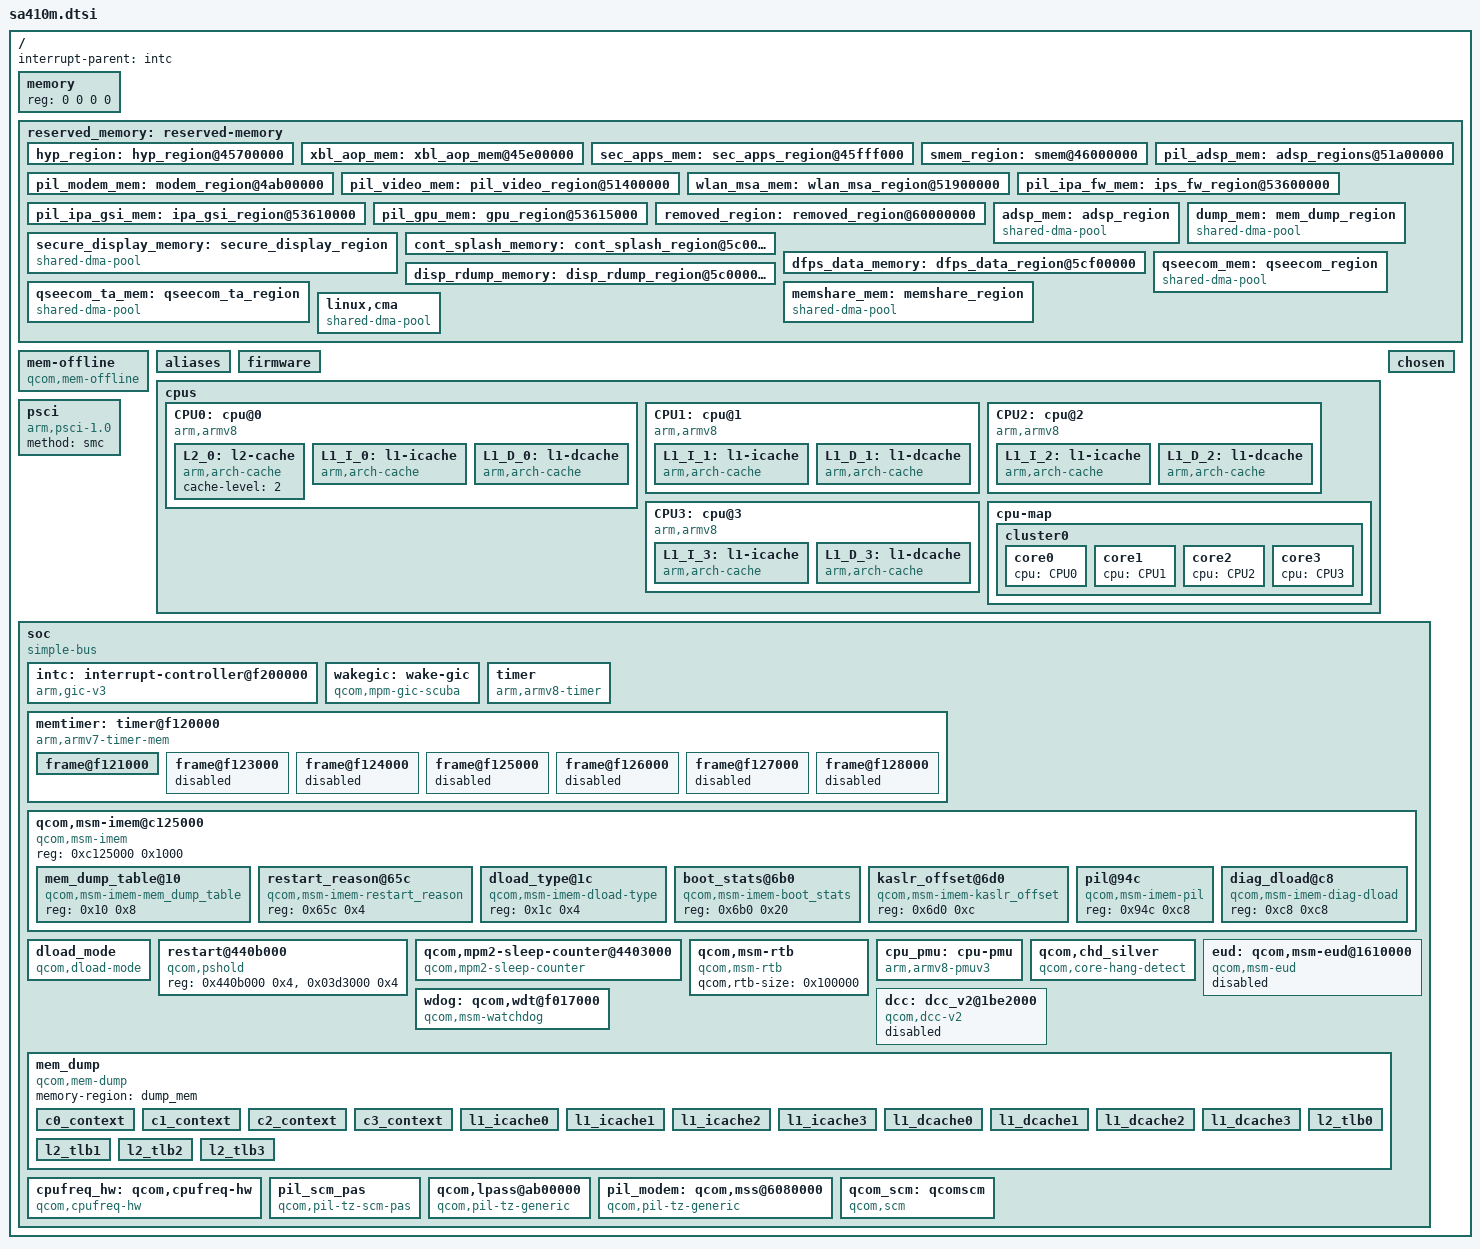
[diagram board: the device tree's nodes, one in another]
#include <dt-bindings/interrupt-controller/arm-gic.h>
#include <dt-bindings/gpio/gpio.h>

/ {
	#address-cells = <2>;
	#size-cells = <2>;
	interrupt-parent = <&intc>;

	memory { device_type = "memory"; reg = <0 0 0 0>; };

	reserved_memory: reserved-memory { };

	mem-offline {
		compatible = "qcom,mem-offline";
		offline-sizes = <0x1 0x40000000 0x0 0x40000000>,
				<0x1 0xc0000000 0x0 0x80000000>,
				<0x2 0xc0000000 0x1 0x40000000>;
		granule = <512>;
	};

	aliases {};

	firmware: firmware {};

	cpus {
		#address-cells = <2>;
		#size-cells = <0>;

		CPU0: cpu@0 {
			device_type = "cpu";
			compatible = "arm,armv8";
			reg = <0x0 0x0>;
			enable-method = "psci";
			capacity-dmips-mhz = <1024>;
			dynamic-power-coefficient = <100>;
			next-level-cache = <&L2_0>;
			qcom,freq-domain = <&cpufreq_hw 0 4>;
			L2_0: l2-cache {
				compatible = "arm,arch-cache";
				cache-level = <2>;
			};

			L1_I_0: l1-icache {
				compatible = "arm,arch-cache";
			};

			L1_D_0: l1-dcache {
				compatible = "arm,arch-cache";
			};
		};

		CPU1: cpu@1 {
			device_type = "cpu";
			compatible = "arm,armv8";
			reg = <0x0 0x1>;
			enable-method = "psci";
			capacity-dmips-mhz = <1024>;
			dynamic-power-coefficient = <100>;
			next-level-cache = <&L2_0>;
			qcom,freq-domain = <&cpufreq_hw 0 4>;

			L1_I_1: l1-icache {
				compatible = "arm,arch-cache";
			};

			L1_D_1: l1-dcache {
				compatible = "arm,arch-cache";
			};
		};

		CPU2: cpu@2 {
			device_type = "cpu";
			compatible = "arm,armv8";
			reg = <0x0 0x2>;
			enable-method = "psci";
			capacity-dmips-mhz = <1024>;
			dynamic-power-coefficient = <100>;
			next-level-cache = <&L2_0>;
			qcom,freq-domain = <&cpufreq_hw 0 4>;

			L1_I_2: l1-icache {
				compatible = "arm,arch-cache";
			};

			L1_D_2: l1-dcache {
				compatible = "arm,arch-cache";
			};
		};

		CPU3: cpu@3 {
			device_type = "cpu";
			compatible = "arm,armv8";
			reg = <0x0 0x3>;
			enable-method = "psci";
			capacity-dmips-mhz = <1024>;
			dynamic-power-coefficient = <100>;
			next-level-cache = <&L2_0>;
			qcom,freq-domain = <&cpufreq_hw 0 4>;

			L1_I_3: l1-icache {
				compatible = "arm,arch-cache";
			};

			L1_D_3: l1-dcache {
				compatible = "arm,arch-cache";
			};
		};

		cpu-map {
			cluster0 {
				core0 {
					cpu = <&CPU0>;
				};

				core1 {
					cpu = <&CPU1>;
				};

				core2 {
					cpu = <&CPU2>;
				};

				core3 {
					cpu = <&CPU3>;
				};
			};
		};
	};

	psci {
		compatible = "arm,psci-1.0";
		method = "smc";
	};

	chosen {
		bootargs = "rcupdate.rcu_expedited=1 rcu_nocbs=0-7";
	};

	soc: soc { };
};

&reserved_memory {
	#address-cells = <2>;
	#size-cells = <2>;
	ranges;

	hyp_region: hyp_region@45700000 {
		no-map;
		reg = <0x0 0x45700000 0x0 0x600000>;
	};

	xbl_aop_mem: xbl_aop_mem@45e00000 {
		no-map;
		reg = <0x0 0x45e00000 0x0 0x100000>;
	};

	sec_apps_mem: sec_apps_region@45fff000 {
		no-map;
		reg = <0x0 0x45fff000 0x0 0x1000>;
	};

	smem_region: smem@46000000 {
		no-map;
		reg = <0x0 0x46000000 0x0 0x200000>;
	};

	pil_modem_mem: modem_region@4ab00000 {
		no-map;
		reg = <0x0 0x4ab00000 0x0 0x6900000>;
	};

	pil_video_mem: pil_video_region@51400000 {
		no-map;
		reg = <0x0 0x51400000 0x0 0x500000>;
	};

	wlan_msa_mem: wlan_msa_region@51900000 {
		no-map;
		reg = <0x0 0x51900000 0x0 0x100000>;
	};

	pil_adsp_mem: adsp_regions@51a00000 {
		no-map;
		reg = <0x0 0x51a00000 0x0 0x1c00000>;
	};

	pil_ipa_fw_mem: ips_fw_region@53600000 {
		no-map;
		reg = <0x0 0x53600000 0x0 0x10000>;
	};

	pil_ipa_gsi_mem: ipa_gsi_region@53610000 {
		no-map;
		reg = <0x0 0x53610000 0x0 0x5000>;
	};

	pil_gpu_mem: gpu_region@53615000 {
		no-map;
		reg = <0x0 0x53615000 0x0 0x2000>;
	};

	removed_region: removed_region@60000000 {
		no-map;
		reg = <0x0 0x60000000 0x0 0x3900000>;
	};

	adsp_mem: adsp_region {
		compatible = "shared-dma-pool";
		alloc-ranges = <0 0x00000000 0 0xffffffff>;
		reusable;
		alignment = <0 0x400000>;
		size = <0 0x800000>;
	};

	dump_mem: mem_dump_region {
		compatible = "shared-dma-pool";
		alloc-ranges = <0x0 0x00000000 0x0 0xffffffff>;
		reusable;
		size = <0 0x800000>;
	};

	secure_display_memory: secure_display_region {
		compatible = "shared-dma-pool";
		alloc-ranges = <0 0x00000000 0 0xffffffff>;
		reusable;
		alignment = <0 0x400000>;
		size = <0 0x5c00000>;
	};

	cont_splash_memory: cont_splash_region@5c000000 {
		reg = <0x0 0x5c000000 0x0 0x00f00000>;
		label = "cont_splash_region";
	};

	dfps_data_memory: dfps_data_region@5cf00000 {
		reg = <0x0 0x5cf00000 0x0 0x0100000>;
		label = "dfps_data_region";
	};

	disp_rdump_memory: disp_rdump_region@5c000000 {
		reg = <0x0 0x5c000000 0x0 0x00f00000>;
		label = "disp_rdump_region";
	};

	qseecom_mem: qseecom_region {
		compatible = "shared-dma-pool";
		alloc-ranges = <0x0 0x00000000 0x0 0xffffffff>;
		reusable;
		alignment = <0x0 0x400000>;
		size = <0x0 0x1400000>;
	};

	qseecom_ta_mem: qseecom_ta_region {
		compatible = "shared-dma-pool";
		alloc-ranges = <0x0 0x00000000 0x0 0xffffffff>;
		reusable;
		alignment = <0x0 0x400000>;
		size = <0x0 0x1000000>;
	};

	memshare_mem: memshare_region {
		compatible = "shared-dma-pool";
		no-map;
		alloc-ranges = <0x0 0x00000000 0x0 0xffffffff>;
		alignment = <0x0 0x100000>;
		size = <0x0 0x800000>;
	};

	/* global autoconfigured region for contiguous allocations */
	linux,cma {
		compatible = "shared-dma-pool";
		alloc-ranges = <0x0 0x00000000 0x0 0xffffffff>;
		reusable;
		alignment = <0x0 0x400000>;
		size = <0x0 0x2000000>;
		linux,cma-default;
	};
};

&soc {
	#address-cells = <1>;
	#size-cells = <1>;
	ranges = <0 0 0 0xffffffff>;
	compatible = "simple-bus";

	intc: interrupt-controller@f200000 {
		compatible = "arm,gic-v3";
		#interrupt-cells = <3>;
		interrupt-controller;
		interrupt-parent = <&intc>;
		#redistributor-regions = <1>;
		redistributor-stride = <0x0 0x20000>;
		reg = <0xf200000 0x10000>,     /* GICD */
		      <0xf300000 0x100000>;    /* GICR * 8 */
		interrupts = <GIC_PPI 9 IRQ_TYPE_LEVEL_HIGH>;
		#gpio-cells = <0>;
	};

	wakegic: wake-gic {
		compatible = "qcom,mpm-gic-scuba", "qcom,mpm";
		interrupts = <GIC_SPI 197 IRQ_TYPE_EDGE_RISING>;
		reg = <0x45f01b8 0x1000>,
			<0x0f40000c 0x4>;  /* MSM_APCS_GCC_BASE 4K */
		reg-names = "vmpm", "ipc";
		qcom,num-mpm-irqs = <96>;
		interrupt-controller;
		interrupt-parent = <&intc>;
		#interrupt-cells = <2>;
	};

	timer {
		compatible = "arm,armv8-timer";
		interrupts = <GIC_PPI 1 (GIC_CPU_MASK_SIMPLE(8) | IRQ_TYPE_LEVEL_LOW)>,
			     <GIC_PPI 2 (GIC_CPU_MASK_SIMPLE(8) | IRQ_TYPE_LEVEL_LOW)>,
			     <GIC_PPI 3 (GIC_CPU_MASK_SIMPLE(8) | IRQ_TYPE_LEVEL_LOW)>,
			     <GIC_PPI 0 (GIC_CPU_MASK_SIMPLE(8) | IRQ_TYPE_LEVEL_LOW)>;
		clock-frequency = <19200000>;
	};

	memtimer: timer@f120000 {
		#address-cells = <1>;
		#size-cells = <1>;
		ranges;
		compatible = "arm,armv7-timer-mem";
		reg = <0xf120000 0x1000>;
		clock-frequency = <19200000>;

		frame@f121000 {
			frame-number = <0>;
			interrupts = <GIC_SPI 8 IRQ_TYPE_LEVEL_HIGH>,
				     <GIC_SPI 7 IRQ_TYPE_LEVEL_HIGH>;
			reg = <0xf121000 0x1000>,
			      <0xf122000 0x1000>;
		};

		frame@f123000 {
			frame-number = <1>;
			interrupts = <GIC_SPI 9 IRQ_TYPE_LEVEL_HIGH>;
			reg = <0xf123000 0x1000>;
			status = "disabled";
		};

		frame@f124000 {
			frame-number = <2>;
			interrupts = <GIC_SPI 10 IRQ_TYPE_LEVEL_HIGH>;
			reg = <0xf124000 0x1000>;
			status = "disabled";
		};

		frame@f125000 {
			frame-number = <3>;
			interrupts = <GIC_SPI 11 IRQ_TYPE_LEVEL_HIGH>;
			reg = <0xf125000 0x1000>;
			status = "disabled";
		};

		frame@f126000 {
			frame-number = <4>;
			interrupts = <GIC_SPI 12 IRQ_TYPE_LEVEL_HIGH>;
			reg = <0xf126000 0x1000>;
			status = "disabled";
		};

		frame@f127000 {
			frame-number = <5>;
			interrupts = <GIC_SPI 13 IRQ_TYPE_LEVEL_HIGH>;
			reg = <0xf127000 0x1000>;
			status = "disabled";
		};

		frame@f128000 {
			frame-number = <6>;
			interrupts = <GIC_SPI 14 IRQ_TYPE_LEVEL_HIGH>;
			reg = <0xf128000 0x1000>;
			status = "disabled";
		};
	};

	qcom,msm-imem@c125000 {
		compatible = "qcom,msm-imem";
		reg = <0xc125000 0x1000>;
		ranges = <0x0 0xc125000 0x1000>;
		#address-cells = <1>;
		#size-cells = <1>;

		mem_dump_table@10 {
			compatible = "qcom,msm-imem-mem_dump_table";
			reg = <0x10 0x8>;
		};

		restart_reason@65c {
			compatible = "qcom,msm-imem-restart_reason";
			reg = <0x65c 0x4>;
		};

		dload_type@1c {
			compatible = "qcom,msm-imem-dload-type";
			reg = <0x1c 0x4>;
		};

		boot_stats@6b0 {
			compatible = "qcom,msm-imem-boot_stats";
			reg = <0x6b0 0x20>;
		};

		kaslr_offset@6d0 {
			compatible = "qcom,msm-imem-kaslr_offset";
			reg = <0x6d0 0xc>;
		};

		pil@94c {
			compatible = "qcom,msm-imem-pil";
			reg = <0x94c 0xc8>;
		};

		diag_dload@c8 {
			compatible = "qcom,msm-imem-diag-dload";
			reg = <0xc8 0xc8>;
		};
	};

	dload_mode {
		compatible = "qcom,dload-mode";
	};

	restart@440b000 {
		compatible = "qcom,pshold";
		reg = <0x440b000 0x4>,
		      <0x03d3000 0x4>;
		reg-names = "pshold-base", "tcsr-boot-misc-detect";
		status="ok";
	};

	qcom,mpm2-sleep-counter@4403000 {
		compatible = "qcom,mpm2-sleep-counter";
		reg = <0x4403000 0x1000>;
		clock-frequency = <32768>;
	};

	qcom,msm-rtb {
		compatible = "qcom,msm-rtb";
		qcom,rtb-size = <0x100000>;
	};

	cpu_pmu: cpu-pmu {
		compatible = "arm,armv8-pmuv3";
		qcom,irq-is-percpu;
		interrupts = <GIC_PPI 6 IRQ_TYPE_LEVEL_HIGH>;
	};

	qcom,chd_silver {
		compatible = "qcom,core-hang-detect";
		label = "silver";
		qcom,threshold-arr = <0x0f1880b0 0x0f1980b0
				      0x0f1a80b0 0x0f1b80b0>;
		qcom,config-arr = <0x0f1880b8 0x0f1980b8
				   0x0f1a80b8 0x0f1b80b8>;
	};

	eud: qcom,msm-eud@1610000 {
		compatible = "qcom,msm-eud";
		interrupt-names = "eud_irq";
		interrupts = <GIC_SPI 189 IRQ_TYPE_LEVEL_HIGH>;
		reg = <0x1610000 0x2000>,
		      <0x1612000 0x1000>,
		      <0x3E5018 0x4>;
		reg-names = "eud_base", "eud_mode_mgr2",
				"eud_tcsr_check_reg";
		qcom,secure-eud-en;
		qcom,eud-tcsr-check-enable;
		qcom,eud-clock-vote-req;
		//clocks = <&gcc GCC_AHB2PHY_USB_CLK>;
		//clock-names = "eud_ahb2phy_clk";
		status = "disabled";
	};

	wdog: qcom,wdt@f017000 {
		compatible = "qcom,msm-watchdog";
		reg = <0xf017000 0x1000>;
		reg-names = "wdt-base";
		interrupts = <GIC_SPI 3 IRQ_TYPE_EDGE_RISING>,
				<GIC_SPI 4 IRQ_TYPE_LEVEL_HIGH>;
		qcom,bark-time = <11000>;
		qcom,pet-time = <9360>;
		qcom,ipi-ping;
		qcom,wakeup-enable;
		status = "ok";
	};

	dcc: dcc_v2@1be2000 {
		compatible = "qcom,dcc-v2";
		reg = <0x1be2000 0x1000>,
			<0x1bee000 0x2000>;
		reg-names = "dcc-base", "dcc-ram-base";
		dcc-ram-offset = <0x2000>;
		status = "disabled";
	};

	mem_dump {
		compatible = "qcom,mem-dump";
		memory-region = <&dump_mem>;

		c0_context {
			qcom,dump-size = <0x800>;
			qcom,dump-id = <0x0>;
		};

		c1_context {
			qcom,dump-size = <0x800>;
			qcom,dump-id = <0x1>;
		};

		c2_context {
			qcom,dump-size = <0x800>;
			qcom,dump-id = <0x2>;
		};

		c3_context {
			qcom,dump-size = <0x800>;
			qcom,dump-id = <0x3>;
		};

		l1_icache0 {
			qcom,dump-size = <0x9040>;
			qcom,dump-id = <0x60>;
		};

		l1_icache1 {
			qcom,dump-size = <0x9040>;
			qcom,dump-id = <0x61>;
		};

		l1_icache2 {
			qcom,dump-size = <0x9040>;
			qcom,dump-id = <0x62>;
		};

		l1_icache3 {
			qcom,dump-size = <0x9040>;
			qcom,dump-id = <0x63>;
		};

		l1_dcache0 {
			qcom,dump-size = <0x9040>;
			qcom,dump-id = <0x80>;
		};

		l1_dcache1 {
			qcom,dump-size = <0x9040>;
			qcom,dump-id = <0x81>;
		};

		l1_dcache2 {
			qcom,dump-size = <0x9040>;
			qcom,dump-id = <0x82>;
		};

		l1_dcache3 {
			qcom,dump-size = <0x9040>;
			qcom,dump-id = <0x83>;
		};

		l2_tlb0 {
			qcom,dump-size = <0x2000>;
			qcom,dump-id = <0x120>;
		};

		l2_tlb1 {
			qcom,dump-size = <0x2000>;
			qcom,dump-id = <0x121>;
		};

		l2_tlb2 {
			qcom,dump-size = <0x2000>;
			qcom,dump-id = <0x122>;
		};

		l2_tlb3 {
			qcom,dump-size = <0x2000>;
			qcom,dump-id = <0x123>;
		};
	};

	cpufreq_hw: qcom,cpufreq-hw {
		compatible = "qcom,cpufreq-hw";
		reg = <0xf521000 0x1400>;
		reg-names = "freq-domain0";
		//clocks = <&rpmcc RPM_SMD_XO_CLK_SRC>, <&gcc GPLL0>;
		//clock-names = "xo", "alternate";
		qcom,no-accumulative-counter;
		qcom,max-lut-entries = <12>;
		#freq-domain-cells = <2>;
		status = "ok";
	};

	pil_scm_pas {
		compatible = "qcom,pil-tz-scm-pas";
		//interconnects = <&clk_virt MASTER_CRYPTO_CORE0 &bimc SLAVE_EBI_CH0>;
	};

	qcom,lpass@ab00000 {
		compatible = "qcom,pil-tz-generic";
		reg = <0xab00000 0x00100>;

		//clocks = <&rpmcc RPM_SMD_XO_CLK_SRC>;
		//clock-names = "xo";
		//qcom,proxy-clock-names = "xo";

		//vdd_lpi_cx-supply = <&VDD_LPI_CX_LEVEL>;
		//qcom,vdd_lpi_cx-uV-uA = <RPMH_REGULATOR_LEVEL_TURBO 0>;
		//vdd_lpi_mx-supply = <&VDD_LPI_MX_LEVEL>;
		//qcom,vdd_lpi_mx-uV-uA = <RPMH_REGULATOR_LEVEL_TURBO 0>;
		qcom,proxy-reg-names = "vdd_lpi_cx", "vdd_lpi_mx";

		qcom,firmware-name = "adsp";
		memory-region = <&pil_adsp_mem>;
		qcom,proxy-timeout-ms = <10000>;
		qcom,sysmon-id = <1>;
		qcom,minidump-id = <5>;
		qcom,ssctl-instance-id = <0x14>;
		qcom,pas-id = <1>;
		qcom,smem-id = <423>;
		qcom,complete-ramdump;
		qcom,minidump-as-elf32;

		/* Inputs from lpass */
		//interrupts-extended = <&intc 0 282 IRQ_TYPE_LEVEL_HIGH>,
		//	<&adsp_smp2p_in 0 0>,
		//	<&adsp_smp2p_in 2 0>,
		//	<&adsp_smp2p_in 1 0>,
		//	<&adsp_smp2p_in 3 0>;

		interrupt-names = "qcom,wdog",
			"qcom,err-fatal",
			"qcom,proxy-unvote",
			"qcom,err-ready",
			"qcom,stop-ack";

		/* Outputs to lpass */
		//qcom,smem-states = <&adsp_smp2p_out 0>;
		qcom,smem-state-names = "qcom,force-stop";
		status = "ok";
	};

	pil_modem: qcom,mss@6080000 {
		compatible = "qcom,pil-tz-generic";
		reg = <0x6080000 0x100>;

		//clocks =  <&rpmcc RPM_SMD_XO_CLK_SRC>;
		//clock-names = "xo";
		//qcom,proxy-clock-names = "xo";

		//vdd_cx-supply = <&VDD_CX_LEVEL>;
		//qcom,vdd_cx-uV-uA = <RPMH_REGULATOR_LEVEL_TURBO 100000>;
		qcom,proxy-reg-names = "vdd_cx";

		qcom,firmware-name = "modem";
		memory-region = <&pil_modem_mem>;
		qcom,proxy-timeout-ms = <10000>;
		qcom,sysmon-id = <0>;
		qcom,ssctl-instance-id = <0x12>;
		qcom,pas-id = <4>;
		qcom,smem-id = <421>;
		qcom,minidump-id = <3>;
		qcom,aux-minidump-ids = <4>;
		qcom,complete-ramdump;
		qcom,sequential-fw-load;

		/* Inputs from mss */
		//interrupts-extended = <&intc 0 307 1>,
		//	<&modem_smp2p_in 0 0>,
		//	<&modem_smp2p_in 2 0>,
		//	<&modem_smp2p_in 1 0>,
		//	<&modem_smp2p_in 3 0>,
		//	<&modem_smp2p_in 7 0>;

		interrupt-names = "qcom,wdog",
			"qcom,err-fatal",
			"qcom,proxy-unvote",
			"qcom,err-ready",
			"qcom,stop-ack",
			"qcom,shutdown-ack";

		/* Outputs to mss */
		//qcom,smem-states = <&modem_smp2p_out 0>;
		qcom,smem-state-names = "qcom,force-stop";
		status = "ok";
	};

	qcom_scm: qcomscm {
		compatible = "qcom,scm";
	};
};

#include "sa410m-pinctrl.dtsi"
#include "scuba-ion.dtsi"
#include "msm-arm-smmu-scuba.dtsi"
